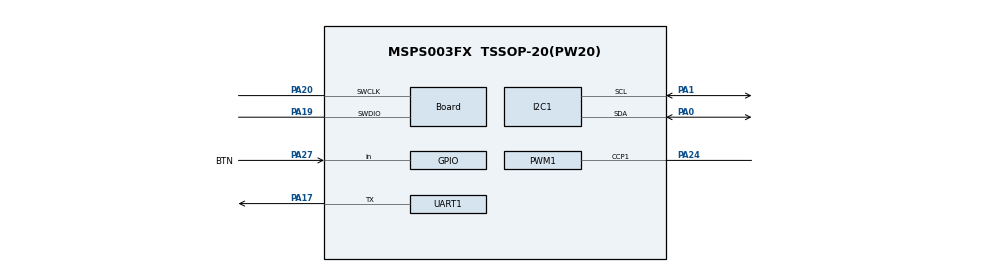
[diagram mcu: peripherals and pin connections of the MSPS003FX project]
/**
 * @cliArgs --device "MSPS003FX" --part "Default" --package "TSSOP-20(PW20)" --product "mspm0_sdk@2.03.00.08"
 * @versions {"tool":"1.22.0+3893"}
 */

/**
 * Import the modules used in this configuration.
 */
const ADC12         = scripting.addModule("/ti/driverlib/ADC12", {}, false);
const ADC121        = ADC12.addInstance();
const Board         = scripting.addModule("/ti/driverlib/Board");
const GPIO          = scripting.addModule("/ti/driverlib/GPIO", {}, false);
const GPIO1         = GPIO.addInstance();
const I2C           = scripting.addModule("/ti/driverlib/I2C", {}, false);
const I2C1          = I2C.addInstance();
const PWM           = scripting.addModule("/ti/driverlib/PWM", {}, false);
const PWM1          = PWM.addInstance();
const SYSCTL        = scripting.addModule("/ti/driverlib/SYSCTL");
const TIMER         = scripting.addModule("/ti/driverlib/TIMER", {}, false);
const TIMER1        = TIMER.addInstance();
const UART          = scripting.addModule("/ti/driverlib/UART", {}, false);
const UART1         = UART.addInstance();
const VREF          = scripting.addModule("/ti/driverlib/VREF");
const ProjectConfig = scripting.addModule("/ti/project_config/ProjectConfig");

/**
 * Write custom configuration values to the imported modules.
 */
ADC121.$name                      = "ADC12_0";
ADC121.samplingOperationMode      = "sequence";
ADC121.endAdd                     = 1;
ADC121.adcMem0vref                = "VREF";
ADC121.adcMem0chansel             = "DL_ADC12_INPUT_CHAN_2";
ADC121.adcMem0_name               = "VBAT";
ADC121.adcMem1_name               = "VUSB";
ADC121.adcMem1chansel             = "DL_ADC12_INPUT_CHAN_4";
ADC121.adcMem1vref                = "VREF";
ADC121.adcMem0avgen               = true;
ADC121.sampleTime0                = "0.05 ms";
ADC121.sampleTime1                = "0.05 ms";
ADC121.hwNumerator                = "DL_ADC12_HW_AVG_NUM_ACC_4";
ADC121.hwDenominator              = "DL_ADC12_HW_AVG_DEN_DIV_BY_4";
ADC121.adcMem1avgen               = true;
ADC121.peripheral.$assign         = "ADC0";
ADC121.peripheral.adcPin2.$assign = "PA25";
ADC121.peripheral.adcPin4.$assign = "PA22";
ADC121.adcPin2Config.$name        = "ti_driverlib_gpio_GPIOPinGeneric4";
ADC121.adcPin4Config.$name        = "ti_driverlib_gpio_GPIOPinGeneric3";

Board.unusedDirection             = "INPUT";
Board.unusedInternalResistor      = "PULL_UP";
Board.genResourceCSV              = true;
Board.genPeriphPinFile            = true;
Board.genResourceCSVAdvanced      = "detailed";
Board.configureUnused             = true;
Board.peripheral.$assign          = "DEBUGSS";
Board.peripheral.swclkPin.$assign = "PA20";
Board.peripheral.swdioPin.$assign = "PA19";
Board.genFileCSV.$name            = "ti_driverlib_ResourcesCSV0";
Board.genFileMod.$name            = "ti_driverlib_BoardPins0";

GPIO1.$name                         = "GPIO_GRP_0";
GPIO1.associatedPins[0].$name       = "BTN";
GPIO1.associatedPins[0].direction   = "INPUT";
GPIO1.associatedPins[0].interruptEn = true;
GPIO1.associatedPins[0].polarity    = "RISE_FALL";
GPIO1.associatedPins[0].pin.$assign = "PA27";

I2C1.$name                           = "I2C_0";
I2C1.basicEnableController           = true;
I2C1.basicControllerStandardBusSpeed = "Fast";
I2C1.advControllerTXFIFOTRIG         = "BYTES_2";
I2C1.peripheral.$assign              = "I2C0";
I2C1.peripheral.sdaPin.$assign       = "PA0";
I2C1.peripheral.sclPin.$assign       = "PA1";
I2C1.sdaPinConfig.$name              = "ti_driverlib_gpio_GPIOPinGeneric0";
I2C1.sclPinConfig.$name              = "ti_driverlib_gpio_GPIOPinGeneric1";

PWM1.$name                      = "PWM_0";
PWM1.pwmMode                    = "EDGE_ALIGN_UP";
PWM1.ccIndex                    = [1];
PWM1.timerStartTimer            = true;
PWM1.timerCount                 = 9999;
PWM1.peripheral.$assign         = "TIMG14";
PWM1.peripheral.ccp1Pin.$assign = "PA24";
PWM1.ccp1PinConfig.$name        = "ti_driverlib_gpio_GPIOPinGeneric5";
PWM1.PWM_CHANNEL_1.$name        = "ti_driverlib_pwm_PWMTimerCC0";

SYSCTL.clockTreeEn   = true;
SYSCTL.nmiWWDT0Behav = "Non-Maskable Interrupt";

TIMER1.$name              = "TIMER_0";
TIMER1.timerMode          = "PERIODIC";
TIMER1.interruptPriority  = "1";
TIMER1.timerClkSrc        = "LFCLK";
TIMER1.interrupts         = ["ZERO"];
TIMER1.timerPeriod        = "1 ms";
TIMER1.peripheral.$assign = "TIMG8";

UART1.$name                    = "UART_0";
UART1.enableFIFO               = true;
UART1.direction                = "TX";
UART1.targetBaudRate           = 230400;
UART1.peripheral.$assign       = "UART0";
UART1.peripheral.txPin.$assign = "PA17";
UART1.txPinConfig.$name        = "ti_driverlib_gpio_GPIOPinGeneric2";

VREF.basicIntVolt = "DL_VREF_BUFCONFIG_OUTPUT_2_5V";

ProjectConfig.migrationCondition = true;
